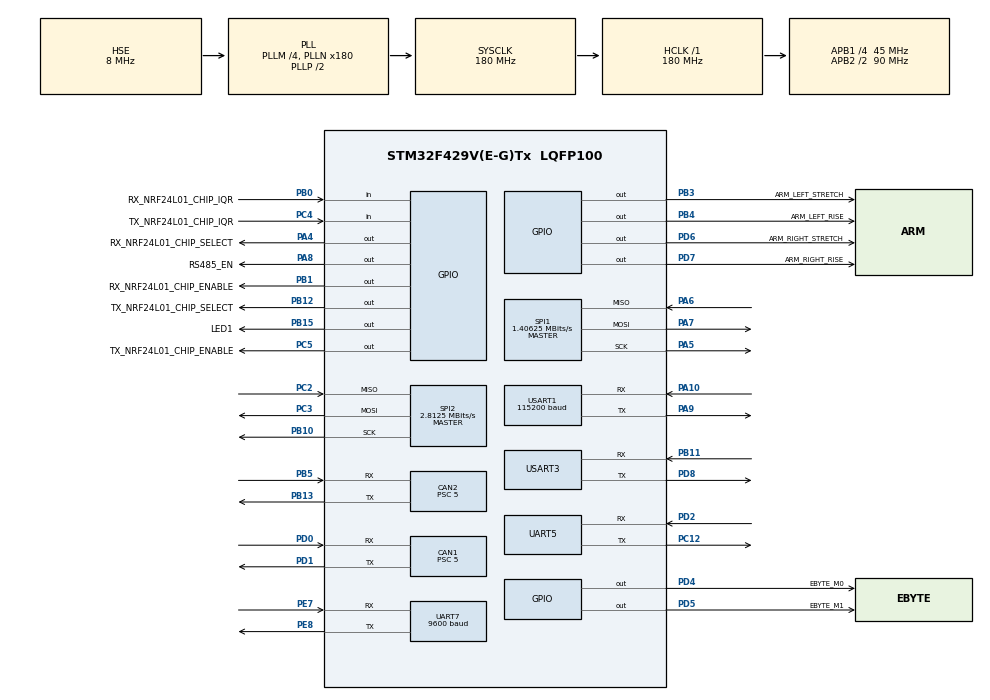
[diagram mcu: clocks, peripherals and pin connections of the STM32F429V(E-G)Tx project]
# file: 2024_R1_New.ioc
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CAN1.BS1=CAN_BS1_4TQ
CAN1.BS2=CAN_BS2_4TQ
CAN1.CalculateBaudRate=1000000
CAN1.CalculateTimeBit=1000
CAN1.CalculateTimeQuantum=111.11111111111111
CAN1.Prescaler=5
CAN2.BS1=CAN_BS1_4TQ
CAN2.BS2=CAN_BS2_4TQ
CAN2.CalculateBaudRate=1000000
CAN2.CalculateTimeBit=1000
CAN2.CalculateTimeQuantum=111.11111111111111
CAN2.Prescaler=5
Dma.Request0=USART3_RX
Dma.USART3_RX.0.Direction=DMA_PERIPH_TO_MEMORY
Dma.USART3_RX.0.FIFOMode=DMA_FIFOMODE_DISABLE
Dma.USART3_RX.0.Instance=DMA1_Stream1
Dma.USART3_RX.0.MemDataAlignment=DMA_MDATAALIGN_BYTE
Dma.USART3_RX.0.MemInc=DMA_MINC_ENABLE
Dma.USART3_RX.0.Mode=DMA_CIRCULAR
Dma.USART3_RX.0.PeriphDataAlignment=DMA_PDATAALIGN_BYTE
Dma.USART3_RX.0.PeriphInc=DMA_PINC_DISABLE
Dma.USART3_RX.0.Priority=DMA_PRIORITY_LOW
FREERTOS.BinarySemaphores01=RobotChassisSemphore,Dynamic,NULL;RobotPlantSemphore,Dynamic,NULL
FREERTOS.INCLUDE_uxTaskGetStackHighWaterMark=1
FREERTOS.Queues01=RobotToChassis,1,uint32_t,0,Dynamic,NULL,NULL;RobotToPlant,1,uint32_t,0,Dynamic,NULL,NULL;ChassisToRobot,1,uint32_t,0,Dynamic,NULL,NULL;PlantToRobot,1,uint32_t,0,Dynamic,NULL,NULL;RobotToShoot,1,uint32_t,0,Dynamic,NULL,NULL;ShootToRobot,1,uint32_t,0,Dynamic,NULL,NULL
FREERTOS.Tasks01=defaultTask,0,128,StartDefaultTask,Default,NULL,Dynamic,NULL,NULL;ChassisTask,0,256,chassis_task,As external,NULL,Dynamic,NULL,NULL;MotorTask,0,128,motor_task,As external,NULL,Dynamic,NULL,NULL;PlantTask,0,128,plant_task,As external,NULL,Dynamic,NULL,NULL;ShootTask,0,128,shoot_task,As external,NULL,Dynamic,NULL,NULL;RobotTask,0,256,robot_task,As external,NULL,Dynamic,NULL,NULL;remoteTask,-3,128,remote_task,As external,NULL,Dynamic,NULL,NULL
Mcu.Family=STM32F4
Mcu.Name=STM32F429V(E-G)Tx
Mcu.Package=LQFP100
NVIC.CAN1_RX0_IRQn=true\:5\:0\:false\:false\:true\:true\:true\:true\:true
NVIC.CAN1_RX1_IRQn=true\:5\:0\:false\:false\:true\:true\:true\:true\:true
NVIC.CAN2_RX0_IRQn=true\:5\:0\:false\:false\:true\:true\:true\:true\:true
NVIC.CAN2_RX1_IRQn=true\:5\:0\:false\:false\:true\:true\:true\:true\:true
NVIC.DMA1_Stream1_IRQn=true\:5\:0\:false\:false\:true\:true\:false\:true\:true
NVIC.PriorityGroup=NVIC_PRIORITYGROUP_4
NVIC.TIM7_IRQn=true\:15\:0\:false\:false\:true\:false\:false\:true\:true
NVIC.TimeBase=TIM7_IRQn
NVIC.TimeBaseIP=TIM7
NVIC.UART5_IRQn=true\:5\:0\:false\:false\:true\:true\:true\:true\:true
NVIC.UART7_IRQn=true\:5\:0\:false\:false\:true\:true\:true\:true\:true
NVIC.USART1_IRQn=true\:5\:0\:false\:false\:true\:true\:true\:true\:true
NVIC.USART3_IRQn=true\:5\:0\:false\:false\:true\:true\:true\:true\:true
PA10.Mode=Asynchronous
PA10.Signal=USART1_RX
PA13.Mode=Serial_Wire
PA13.Signal=SYS_JTMS-SWDIO
PA14.Mode=Serial_Wire
PA14.Signal=SYS_JTCK-SWCLK
PA4.GPIO_Label=RX_NRF24L01_CHIP_SELECT
PA4.Signal=GPIO_Output
PA5.Mode=Full_Duplex_Master
PA5.Signal=SPI1_SCK
PA6.Mode=Full_Duplex_Master
PA6.Signal=SPI1_MISO
PA7.Mode=Full_Duplex_Master
PA7.Signal=SPI1_MOSI
PA8.GPIO_Label=RS485_EN
PA8.Signal=GPIO_Output
PA9.Mode=Asynchronous
PA9.Signal=USART1_TX
PB0.GPIO_Label=RX_NRF24L01_CHIP_IQR
PB0.Signal=GPIO_Input
PB1.GPIO_Label=RX_NRF24L01_CHIP_ENABLE
PB1.Signal=GPIO_Output
PB10.Mode=Full_Duplex_Master
PB10.Signal=SPI2_SCK
PB11.Mode=Asynchronous
PB11.Signal=USART3_RX
PB12.GPIO_Label=TX_NRF24L01_CHIP_SELECT
PB12.Signal=GPIO_Output
PB13.Mode=CAN_Activate
PB13.Signal=CAN2_TX
PB15.GPIO_Label=LED1
PB15.PinState=GPIO_PIN_RESET
PB15.Signal=GPIO_Output
PB3.GPIO_Label=ARM_LEFT_STRETCH
PB3.GPIO_ModeDefaultOutputPP=GPIO_MODE_OUTPUT_PP
PB3.GPIO_PuPd=GPIO_NOPULL
PB3.PinState=GPIO_PIN_RESET
PB3.Signal=GPIO_Output
PB4.GPIO_Label=ARM_LEFT_RISE
PB4.Signal=GPIO_Output
PB5.Mode=CAN_Activate
PB5.Signal=CAN2_RX
PC12.Mode=Asynchronous
PC12.Signal=UART5_TX
PC2.Mode=Full_Duplex_Master
PC2.Signal=SPI2_MISO
PC3.Mode=Full_Duplex_Master
PC3.Signal=SPI2_MOSI
PC4.GPIO_Label=TX_NRF24L01_CHIP_IQR
PC4.Signal=GPIO_Input
PC5.GPIO_Label=TX_NRF24L01_CHIP_ENABLE
PC5.Signal=GPIO_Output
PD0.Mode=CAN_Activate
PD0.Signal=CAN1_RX
PD1.Mode=CAN_Activate
PD1.Signal=CAN1_TX
PD2.Mode=Asynchronous
PD2.Signal=UART5_RX
PD4.GPIO_Label=EBYTE_M0
PD4.PinState=GPIO_PIN_RESET
PD4.Signal=GPIO_Output
PD5.GPIO_Label=EBYTE_M1
PD5.Signal=GPIO_Output
PD6.GPIO_Label=ARM_RIGHT_STRETCH
PD6.GPIO_ModeDefaultOutputPP=GPIO_MODE_OUTPUT_PP
PD6.GPIO_PuPd=GPIO_NOPULL
PD6.PinState=GPIO_PIN_RESET
PD6.Signal=GPIO_Output
PD7.GPIO_Label=ARM_RIGHT_RISE
PD7.GPIO_ModeDefaultOutputPP=GPIO_MODE_OUTPUT_PP
PD7.GPIO_PuPd=GPIO_NOPULL
PD7.PinState=GPIO_PIN_RESET
PD7.Signal=GPIO_Output
PD8.Mode=Asynchronous
PD8.Signal=USART3_TX
PE7.Mode=Asynchronous
PE7.Signal=UART7_RX
PE8.Mode=Asynchronous
PE8.Signal=UART7_TX
PH0/OSC_IN.Mode=HSE-External-Clock-Source
PH0/OSC_IN.Signal=RCC_OSC_IN
PH1/OSC_OUT.Mode=HSE-External-Clock-Source
PH1/OSC_OUT.Signal=RCC_OSC_OUT
ProjectManager.HeapSize=0x200
ProjectManager.StackSize=0x400
ProjectManager.TargetToolchain=MDK-ARM V5.32
RCC.48MHZClocksFreq_Value=90000000
RCC.AHBFreq_Value=180000000
RCC.APB1CLKDivider=RCC_HCLK_DIV4
RCC.APB1Freq_Value=45000000
RCC.APB1TimFreq_Value=90000000
RCC.APB2CLKDivider=RCC_HCLK_DIV2
RCC.APB2Freq_Value=90000000
RCC.APB2TimFreq_Value=180000000
RCC.CortexFreq_Value=180000000
RCC.HCLKFreq_Value=180000000
RCC.HSE_VALUE=8000000
RCC.HSI_VALUE=16000000
RCC.LSE_VALUE=32768
RCC.PLLM=4
RCC.PLLN=180
RCC.PLLSourceVirtual=RCC_PLLSOURCE_HSE
RCC.SYSCLKFreq_VALUE=180000000
RCC.SYSCLKSource=RCC_SYSCLKSOURCE_PLLCLK
RCC.VCOOutputFreq_Value=360000000
SPI1.BaudRatePrescaler=SPI_BAUDRATEPRESCALER_64
SPI1.CLKPhase=SPI_PHASE_1EDGE
SPI1.CalculateBaudRate=1.40625 MBits/s
SPI1.Direction=SPI_DIRECTION_2LINES
SPI1.Mode=SPI_MODE_MASTER
SPI1.VirtualType=VM_MASTER
SPI2.BaudRatePrescaler=SPI_BAUDRATEPRESCALER_16
SPI2.CalculateBaudRate=2.8125 MBits/s
SPI2.Direction=SPI_DIRECTION_2LINES
SPI2.Mode=SPI_MODE_MASTER
SPI2.VirtualType=VM_MASTER
STMicroelectronics.X-CUBE-ALGOBUILD.1.3.0.LibraryCcDSPOoLibraryJjDSPOoLibrary=true
UART5.VirtualMode=Asynchronous
UART7.BaudRate=9600
UART7.VirtualMode=Asynchronous
USART1.BaudRate=115200
USART1.VirtualMode=VM_ASYNC
USART3.VirtualMode=VM_ASYNC
VP_FREERTOS_VS_CMSIS_V1.Mode=CMSIS_V1
VP_STMicroelectronics.X-CUBE-ALGOBUILD_VS_DSPOoLibraryJjLibrary_1.3.0_1.3.0.Mode=DSPOoLibraryJjLibrary
VP_SYS_VS_tim7.Mode=TIM7
board=custom

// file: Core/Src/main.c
/* USER CODE BEGIN Header */
/**
  ******************************************************************************
  * @file           : main.c
  * @brief          : Main program body
  ******************************************************************************
  * @attention
  *
  * Copyright (c) 2024 STMicroelectronics.
  * All rights reserved.
  *
  * This software is licensed under terms that can be found in the LICENSE file
  * in the root directory of this software component.
  * If no LICENSE file comes with this software, it is provided AS-IS.
  *
  ******************************************************************************
  */
/* USER CODE END Header */
#include "main.h"
#include "cmsis_os.h"
#include "can.h"
#include "dma.h"
#include "spi.h"
#include "usart.h"
#include "gpio.h"

/* USER CODE BEGIN Includes */
#include "bsp_can.h"
#include "remote_task.h"
//#include "bsp_rc.h"
#include "ops_receive.h"
#include "servo.h"
#include "plant_task.h"
//#include "nrf24l01function.h"
#include "nrf24l01.h"

/* USER CODE END Includes */

/* USER CODE BEGIN PV */

/* Extern   variables ---------------------------------------------------------*/

/* Extern   function prototypes -----------------------------------------------*/
/* USER CODE END PV */

void SystemClock_Config(void);
void MX_FREERTOS_Init(void);

/* USER CODE BEGIN 0 */
extern uint8_t rec;
//uint8_t test=0x00;
/* USER CODE END 0 */

int main(void)
{

  /* MCU Configuration--------------------------------------------------------*/

  /* Reset of all peripherals, Initializes the Flash interface and the Systick. */
  HAL_Init();

  /* Configure the system clock */
  SystemClock_Config();

  /* Initialize all configured peripherals */
  MX_GPIO_Init();
  MX_DMA_Init();
  MX_CAN1_Init();
  MX_CAN2_Init();
  MX_UART7_Init();
  MX_USART1_UART_Init();
  MX_USART3_UART_Init();
  MX_UART5_Init();
  MX_SPI1_Init();
  MX_SPI2_Init();
  /* USER CODE BEGIN 2 */
	CAN_Filter_Init();
	dbus_uart_init();
	HAL_UART_Receive_IT(&OPS_USART,&rec,1);
  /* USER CODE END 2 */

  /* Call init function for freertos objects (in freertos.c) */
  MX_FREERTOS_Init();

  /* Start scheduler */
  osKernelStart();

  /* We should never get here as control is now taken by the scheduler */
  /* Infinite loop */
  while (1)
  {

  }
}

void SystemClock_Config(void)
{
  RCC_OscInitTypeDef RCC_OscInitStruct = {0};
  RCC_ClkInitTypeDef RCC_ClkInitStruct = {0};

  /** Configure the main internal regulator output voltage
  */
  __HAL_RCC_PWR_CLK_ENABLE();
  __HAL_PWR_VOLTAGESCALING_CONFIG(PWR_REGULATOR_VOLTAGE_SCALE1);

  /** Initializes the RCC Oscillators according to the specified parameters
  * in the RCC_OscInitTypeDef structure.
  */
  RCC_OscInitStruct.OscillatorType = RCC_OSCILLATORTYPE_HSE;
  RCC_OscInitStruct.HSEState = RCC_HSE_BYPASS;
  RCC_OscInitStruct.PLL.PLLState = RCC_PLL_ON;
  RCC_OscInitStruct.PLL.PLLSource = RCC_PLLSOURCE_HSE;
  RCC_OscInitStruct.PLL.PLLM = 4;
  RCC_OscInitStruct.PLL.PLLN = 180;
  RCC_OscInitStruct.PLL.PLLP = RCC_PLLP_DIV2;
  RCC_OscInitStruct.PLL.PLLQ = 4;
  if (HAL_RCC_OscConfig(&RCC_OscInitStruct) != HAL_OK)
  {
    Error_Handler();
  }

  /** Activate the Over-Drive mode
  */
  if (HAL_PWREx_EnableOverDrive() != HAL_OK)
  {
    Error_Handler();
  }

  /** Initializes the CPU, AHB and APB buses clocks
  */
  RCC_ClkInitStruct.ClockType = RCC_CLOCKTYPE_HCLK|RCC_CLOCKTYPE_SYSCLK
                              |RCC_CLOCKTYPE_PCLK1|RCC_CLOCKTYPE_PCLK2;
  RCC_ClkInitStruct.SYSCLKSource = RCC_SYSCLKSOURCE_PLLCLK;
  RCC_ClkInitStruct.AHBCLKDivider = RCC_SYSCLK_DIV1;
  RCC_ClkInitStruct.APB1CLKDivider = RCC_HCLK_DIV4;
  RCC_ClkInitStruct.APB2CLKDivider = RCC_HCLK_DIV2;

  if (HAL_RCC_ClockConfig(&RCC_ClkInitStruct, FLASH_LATENCY_5) != HAL_OK)
  {
    Error_Handler();
  }
}

void HAL_TIM_PeriodElapsedCallback(TIM_HandleTypeDef *htim)
{
  if (htim->Instance == TIM7) {
    HAL_IncTick();
  }
}

void Error_Handler(void)
{
  __disable_irq();
  while (1)
  {
  }
}

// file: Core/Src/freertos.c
/* USER CODE BEGIN Header */
/**
  ******************************************************************************
  * File Name          : freertos.c
  * Description        : Code for freertos applications
  ******************************************************************************
  * @attention
  *
  * Copyright (c) 2024 STMicroelectronics.
  * All rights reserved.
  *
  * This software is licensed under terms that can be found in the LICENSE file
  * in the root directory of this software component.
  * If no LICENSE file comes with this software, it is provided AS-IS.
  *
  ******************************************************************************
  */
/* USER CODE END Header */

#include "FreeRTOS.h"
#include "task.h"
#include "main.h"
#include "cmsis_os.h"

osThreadId defaultTaskHandle;
osThreadId ChassisTaskHandle;
osThreadId MotorTaskHandle;
osThreadId PlantTaskHandle;
osThreadId ShootTaskHandle;
osThreadId RobotTaskHandle;
osThreadId remoteTaskHandle;
osMessageQId RobotToChassisHandle;
osMessageQId RobotToPlantHandle;
osMessageQId ChassisToRobotHandle;
osMessageQId PlantToRobotHandle;
osMessageQId RobotToShootHandle;
osMessageQId ShootToRobotHandle;
osSemaphoreId RobotChassisSemphoreHandle;
osSemaphoreId RobotPlantSemphoreHandle;

void StartDefaultTask(void const * argument);
extern void chassis_task(void const * argument);
extern void motor_task(void const * argument);
extern void plant_task(void const * argument);
extern void shoot_task(void const * argument);
extern void robot_task(void const * argument);
extern void remote_task(void const * argument);

void MX_FREERTOS_Init(void); /* (MISRA C 2004 rule 8.1) */

/* GetIdleTaskMemory prototype (linked to static allocation support) */
void vApplicationGetIdleTaskMemory( StaticTask_t **ppxIdleTaskTCBBuffer, StackType_t **ppxIdleTaskStackBuffer, uint32_t *pulIdleTaskStackSize );

/* USER CODE BEGIN GET_IDLE_TASK_MEMORY */
static StaticTask_t xIdleTaskTCBBuffer;
static StackType_t xIdleStack[configMINIMAL_STACK_SIZE];

void vApplicationGetIdleTaskMemory( StaticTask_t **ppxIdleTaskTCBBuffer, StackType_t **ppxIdleTaskStackBuffer, uint32_t *pulIdleTaskStackSize )
{
  *ppxIdleTaskTCBBuffer = &xIdleTaskTCBBuffer;
  *ppxIdleTaskStackBuffer = &xIdleStack[0];
  *pulIdleTaskStackSize = configMINIMAL_STACK_SIZE;
  /* place for user code */
}
/* USER CODE END GET_IDLE_TASK_MEMORY */

void MX_FREERTOS_Init(void) {

  /* Create the semaphores(s) */
  /* definition and creation of RobotChassisSemphore */
  osSemaphoreDef(RobotChassisSemphore);
  RobotChassisSemphoreHandle = osSemaphoreCreate(osSemaphore(RobotChassisSemphore), 1);

  /* definition and creation of RobotPlantSemphore */
  osSemaphoreDef(RobotPlantSemphore);
  RobotPlantSemphoreHandle = osSemaphoreCreate(osSemaphore(RobotPlantSemphore), 1);

  /* Create the queue(s) */
  /* definition and creation of RobotToChassis */
  osMessageQDef(RobotToChassis, 1, uint32_t);
  RobotToChassisHandle = osMessageCreate(osMessageQ(RobotToChassis), NULL);

  /* definition and creation of RobotToPlant */
  osMessageQDef(RobotToPlant, 1, uint32_t);
  RobotToPlantHandle = osMessageCreate(osMessageQ(RobotToPlant), NULL);

  /* definition and creation of ChassisToRobot */
  osMessageQDef(ChassisToRobot, 1, uint32_t);
  ChassisToRobotHandle = osMessageCreate(osMessageQ(ChassisToRobot), NULL);

  /* definition and creation of PlantToRobot */
  osMessageQDef(PlantToRobot, 1, uint32_t);
  PlantToRobotHandle = osMessageCreate(osMessageQ(PlantToRobot), NULL);

  /* definition and creation of RobotToShoot */
  osMessageQDef(RobotToShoot, 1, uint32_t);
  RobotToShootHandle = osMessageCreate(osMessageQ(RobotToShoot), NULL);

  /* definition and creation of ShootToRobot */
  osMessageQDef(ShootToRobot, 1, uint32_t);
  ShootToRobotHandle = osMessageCreate(osMessageQ(ShootToRobot), NULL);

  /* Create the thread(s) */
  /* definition and creation of defaultTask */
  osThreadDef(defaultTask, StartDefaultTask, osPriorityNormal, 0, 128);
  defaultTaskHandle = osThreadCreate(osThread(defaultTask), NULL);

  /* definition and creation of ChassisTask */
  osThreadDef(ChassisTask, chassis_task, osPriorityNormal, 0, 256);
  ChassisTaskHandle = osThreadCreate(osThread(ChassisTask), NULL);

  /* definition and creation of MotorTask */
  osThreadDef(MotorTask, motor_task, osPriorityNormal, 0, 128);
  MotorTaskHandle = osThreadCreate(osThread(MotorTask), NULL);

  /* definition and creation of PlantTask */
  osThreadDef(PlantTask, plant_task, osPriorityNormal, 0, 128);
  PlantTaskHandle = osThreadCreate(osThread(PlantTask), NULL);

  /* definition and creation of ShootTask */
  osThreadDef(ShootTask, shoot_task, osPriorityNormal, 0, 128);
  ShootTaskHandle = osThreadCreate(osThread(ShootTask), NULL);

  /* definition and creation of RobotTask */
  osThreadDef(RobotTask, robot_task, osPriorityNormal, 0, 256);
  RobotTaskHandle = osThreadCreate(osThread(RobotTask), NULL);

  /* definition and creation of remoteTask */
  osThreadDef(remoteTask, remote_task, osPriorityIdle, 0, 128);
  remoteTaskHandle = osThreadCreate(osThread(remoteTask), NULL);

}

void StartDefaultTask(void const * argument)
{
  for(;;)
  {
    osDelay(1);
  }
}
